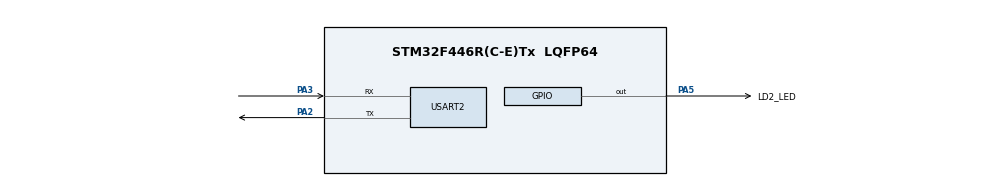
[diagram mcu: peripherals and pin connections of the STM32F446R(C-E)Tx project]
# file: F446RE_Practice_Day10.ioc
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FREERTOS.Tasks01=defaultTask,24,128,StartDefaultTask,Default,NULL,Dynamic,NULL,NULL;WorkerTask,24,512,StartWorkerTask,Default,NULL,Dynamic,NULL,NULL;MonitorTask,16,512,StartMonitorTask,Default,NULL,Dynamic,NULL,NULL
FREERTOS.configUSE_NEWLIB_REENTRANT=1
Mcu.Family=STM32F4
Mcu.Name=STM32F446R(C-E)Tx
Mcu.Package=LQFP64
NVIC.PriorityGroup=NVIC_PRIORITYGROUP_4
NVIC.TIM6_DAC_IRQn=true\:15\:0\:false\:false\:true\:false\:false\:true\:true
NVIC.TimeBase=TIM6_DAC_IRQn
NVIC.TimeBaseIP=TIM6
PA13.Mode=Serial_Wire
PA13.Signal=SYS_JTMS-SWDIO
PA14.Mode=Serial_Wire
PA14.Signal=SYS_JTCK-SWCLK
PA2.Mode=Asynchronous
PA2.Signal=USART2_TX
PA3.Mode=Asynchronous
PA3.Signal=USART2_RX
PA5.GPIO_Label=LD2_LED
PA5.Signal=GPIO_Output
ProjectManager.HeapSize=0x200
ProjectManager.StackSize=0x400
ProjectManager.TargetToolchain=STM32CubeIDE
RCC.CortexFreq_Value=16000000
RCC.USBFreq_Value=96000000
RCC.VCOOutputFreq_Value=192000000
USART2.VirtualMode=VM_ASYNC
VP_FREERTOS_VS_CMSIS_V2.Mode=CMSIS_V2
VP_SYS_VS_tim6.Mode=TIM6
board=custom

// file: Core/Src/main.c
/* USER CODE BEGIN Header */
/**
  ******************************************************************************
  * @file           : main.c
  * @brief          : Main program body
  ******************************************************************************
  * @attention
  *
  * Copyright (c) 2026 STMicroelectronics.
  * All rights reserved.
  *
  * This software is licensed under terms that can be found in the LICENSE file
  * in the root directory of this software component.
  * If no LICENSE file comes with this software, it is provided AS-IS.
  *
  ******************************************************************************
  */
/* USER CODE END Header */
#include "main.h"
#include "cmsis_os.h"

/* USER CODE BEGIN Includes */

#include <stdio.h>

/* USER CODE END Includes */

/* USER CODE BEGIN PD */

#define STACK_WARNING_BYTES 128U

/* USER CODE END PD */

UART_HandleTypeDef huart2;

/* Definitions for defaultTask */
osThreadId_t defaultTaskHandle;
const osThreadAttr_t defaultTask_attributes = {
  .name = "defaultTask",
  .stack_size = 128 * 4,
  .priority = (osPriority_t) osPriorityNormal,
};
/* Definitions for WorkerTask */
osThreadId_t WorkerTaskHandle;
const osThreadAttr_t WorkerTask_attributes = {
  .name = "WorkerTask",
  .stack_size = 512 * 4,
  .priority = (osPriority_t) osPriorityNormal,
};
/* Definitions for MonitorTask */
osThreadId_t MonitorTaskHandle;
const osThreadAttr_t MonitorTask_attributes = {
  .name = "MonitorTask",
  .stack_size = 512 * 4,
  .priority = (osPriority_t) osPriorityBelowNormal,
};
/* USER CODE BEGIN PV */

volatile uint32_t worker_stack_free_bytes = 0U;
volatile uint32_t worker_loop_count = 0U;
volatile uint32_t worker_checksum = 0U;

/* USER CODE END PV */

void SystemClock_Config(void);
static void MX_GPIO_Init(void);
static void MX_USART2_UART_Init(void);
void StartDefaultTask(void *argument);
void StartWorkerTask(void *argument);
void StartMonitorTask(void *argument);

int main(void)
{

  /* MCU Configuration--------------------------------------------------------*/

  /* Reset of all peripherals, Initializes the Flash interface and the Systick. */
  HAL_Init();

  /* Configure the system clock */
  SystemClock_Config();

  /* Initialize all configured peripherals */
  MX_GPIO_Init();
  MX_USART2_UART_Init();

  /* Init scheduler */
  osKernelInitialize();

  /* Create the thread(s) */
  /* creation of defaultTask */
  defaultTaskHandle = osThreadNew(StartDefaultTask, NULL, &defaultTask_attributes);

  /* creation of WorkerTask */
  WorkerTaskHandle = osThreadNew(StartWorkerTask, NULL, &WorkerTask_attributes);

  /* creation of MonitorTask */
  MonitorTaskHandle = osThreadNew(StartMonitorTask, NULL, &MonitorTask_attributes);

  /* Start scheduler */
  osKernelStart();

  /* We should never get here as control is now taken by the scheduler */

  /* Infinite loop */
  while (1)
  {

  }
}

void SystemClock_Config(void)
{
  RCC_OscInitTypeDef RCC_OscInitStruct = {0};
  RCC_ClkInitTypeDef RCC_ClkInitStruct = {0};

  /** Configure the main internal regulator output voltage
  */
  __HAL_RCC_PWR_CLK_ENABLE();
  __HAL_PWR_VOLTAGESCALING_CONFIG(PWR_REGULATOR_VOLTAGE_SCALE3);

  /** Initializes the RCC Oscillators according to the specified parameters
  * in the RCC_OscInitTypeDef structure.
  */
  RCC_OscInitStruct.OscillatorType = RCC_OSCILLATORTYPE_HSI;
  RCC_OscInitStruct.HSIState = RCC_HSI_ON;
  RCC_OscInitStruct.HSICalibrationValue = RCC_HSICALIBRATION_DEFAULT;
  RCC_OscInitStruct.PLL.PLLState = RCC_PLL_NONE;
  if (HAL_RCC_OscConfig(&RCC_OscInitStruct) != HAL_OK)
  {
    Error_Handler();
  }

  /** Initializes the CPU, AHB and APB buses clocks
  */
  RCC_ClkInitStruct.ClockType = RCC_CLOCKTYPE_HCLK|RCC_CLOCKTYPE_SYSCLK
                              |RCC_CLOCKTYPE_PCLK1|RCC_CLOCKTYPE_PCLK2;
  RCC_ClkInitStruct.SYSCLKSource = RCC_SYSCLKSOURCE_HSI;
  RCC_ClkInitStruct.AHBCLKDivider = RCC_SYSCLK_DIV1;
  RCC_ClkInitStruct.APB1CLKDivider = RCC_HCLK_DIV1;
  RCC_ClkInitStruct.APB2CLKDivider = RCC_HCLK_DIV1;

  if (HAL_RCC_ClockConfig(&RCC_ClkInitStruct, FLASH_LATENCY_0) != HAL_OK)
  {
    Error_Handler();
  }
}

static void MX_USART2_UART_Init(void)
{

  huart2.Instance = USART2;
  huart2.Init.BaudRate = 115200;
  huart2.Init.WordLength = UART_WORDLENGTH_8B;
  huart2.Init.StopBits = UART_STOPBITS_1;
  huart2.Init.Parity = UART_PARITY_NONE;
  huart2.Init.Mode = UART_MODE_TX_RX;
  huart2.Init.HwFlowCtl = UART_HWCONTROL_NONE;
  huart2.Init.OverSampling = UART_OVERSAMPLING_16;
  if (HAL_UART_Init(&huart2) != HAL_OK)
  {
    Error_Handler();
  }

}

static void MX_GPIO_Init(void)
{
  GPIO_InitTypeDef GPIO_InitStruct = {0};

  /* GPIO Ports Clock Enable */
  __HAL_RCC_GPIOA_CLK_ENABLE();

  /*Configure GPIO pin Output Level */
  HAL_GPIO_WritePin(LD2_LED_GPIO_Port, LD2_LED_Pin, GPIO_PIN_RESET);

  /*Configure GPIO pin : LD2_LED_Pin */
  GPIO_InitStruct.Pin = LD2_LED_Pin;
  GPIO_InitStruct.Mode = GPIO_MODE_OUTPUT_PP;
  GPIO_InitStruct.Pull = GPIO_NOPULL;
  GPIO_InitStruct.Speed = GPIO_SPEED_FREQ_LOW;
  HAL_GPIO_Init(LD2_LED_GPIO_Port, &GPIO_InitStruct);

}

void StartDefaultTask(void *argument)
{
  for(;;)
  {
    osDelay(1);
  }
}

void StartWorkerTask(void *argument)
{
    /*
     * volatile 避免編譯器把整個陣列最佳化掉。
     * 這個陣列會占用 WorkerTask 的 Stack。
     */
    volatile uint8_t work_buffer[1784];

    uint32_t pattern = 0U;

    for (;;)
    {
        uint32_t sum = 0U;

        for (uint32_t i = 0U;
             i < sizeof(work_buffer);
             i++)
        {
            work_buffer[i] =
                (uint8_t)(i + pattern);

            sum += work_buffer[i];
        }

        worker_checksum = sum;
        worker_loop_count++;

        pattern++;

        osDelay(100U);
    }
  /* USER CODE END StartWorkerTask */
}

void StartMonitorTask(void *argument)
{
	    char message[96];

	    for (;;)
	    {
	        /*
	         * CMSIS-RTOS2 回傳目前曾經剩下的最小 Stack 空間，
	         * 單位通常為 Bytes。
	         */
	        worker_stack_free_bytes =
	            osThreadGetStackSpace(WorkerTaskHandle);

	        if (worker_stack_free_bytes <
	            STACK_WARNING_BYTES)
	        {
	            HAL_GPIO_WritePin(
	                GPIOA,
	                GPIO_PIN_5,
	                GPIO_PIN_SET);
	        }
	        else
	        {
	            HAL_GPIO_WritePin(
	                GPIOA,
	                GPIO_PIN_5,
	                GPIO_PIN_RESET);
	        }

	        int length = snprintf(
	            message,
	            sizeof(message),
	            "Worker loop=%lu, checksum=%lu, "
	            "minimum stack free=%lu bytes\r\n",
	            (unsigned long)worker_loop_count,
	            (unsigned long)worker_checksum,
	            (unsigned long)worker_stack_free_bytes);

	        if (length > 0)
	        {
	            HAL_UART_Transmit(
	                &huart2,
	                (uint8_t *)message,
	                (uint16_t)length,
	                100U);
	        }

	        osDelay(1000U);
	    }
  /* USER CODE END StartMonitorTask */
}

void HAL_TIM_PeriodElapsedCallback(TIM_HandleTypeDef *htim)
{
  if (htim->Instance == TIM6)
  {
    HAL_IncTick();
  }
}

void Error_Handler(void)
{
  __disable_irq();
  while (1)
  {
  }
}

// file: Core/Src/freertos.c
/* USER CODE BEGIN Header */
/**
  ******************************************************************************
  * File Name          : freertos.c
  * Description        : Code for freertos applications
  ******************************************************************************
  * @attention
  *
  * Copyright (c) 2026 STMicroelectronics.
  * All rights reserved.
  *
  * This software is licensed under terms that can be found in the LICENSE file
  * in the root directory of this software component.
  * If no LICENSE file comes with this software, it is provided AS-IS.
  *
  ******************************************************************************
  */
/* USER CODE END Header */

#include "FreeRTOS.h"
#include "task.h"
#include "main.h"

/* USER CODE BEGIN Variables */

volatile uint32_t stack_overflow_detected = 0U;

/* USER CODE END Variables */

/* USER CODE BEGIN Application */

void vApplicationStackOverflowHook(
    TaskHandle_t xTask,
    char *pcTaskName)
{
    (void)xTask;
    (void)pcTaskName;

    stack_overflow_detected = 1U;

    /*
     * 直接點亮 LED，表示偵測到嚴重錯誤。
     */
    HAL_GPIO_WritePin(
        GPIOA,
        GPIO_PIN_5,
        GPIO_PIN_SET);

    /*
     * Debug 模式下停在這裡。
     */
    __BKPT(0);

    taskDISABLE_INTERRUPTS();

    while (1)
    {
    }
}

/* USER CODE END Application */
